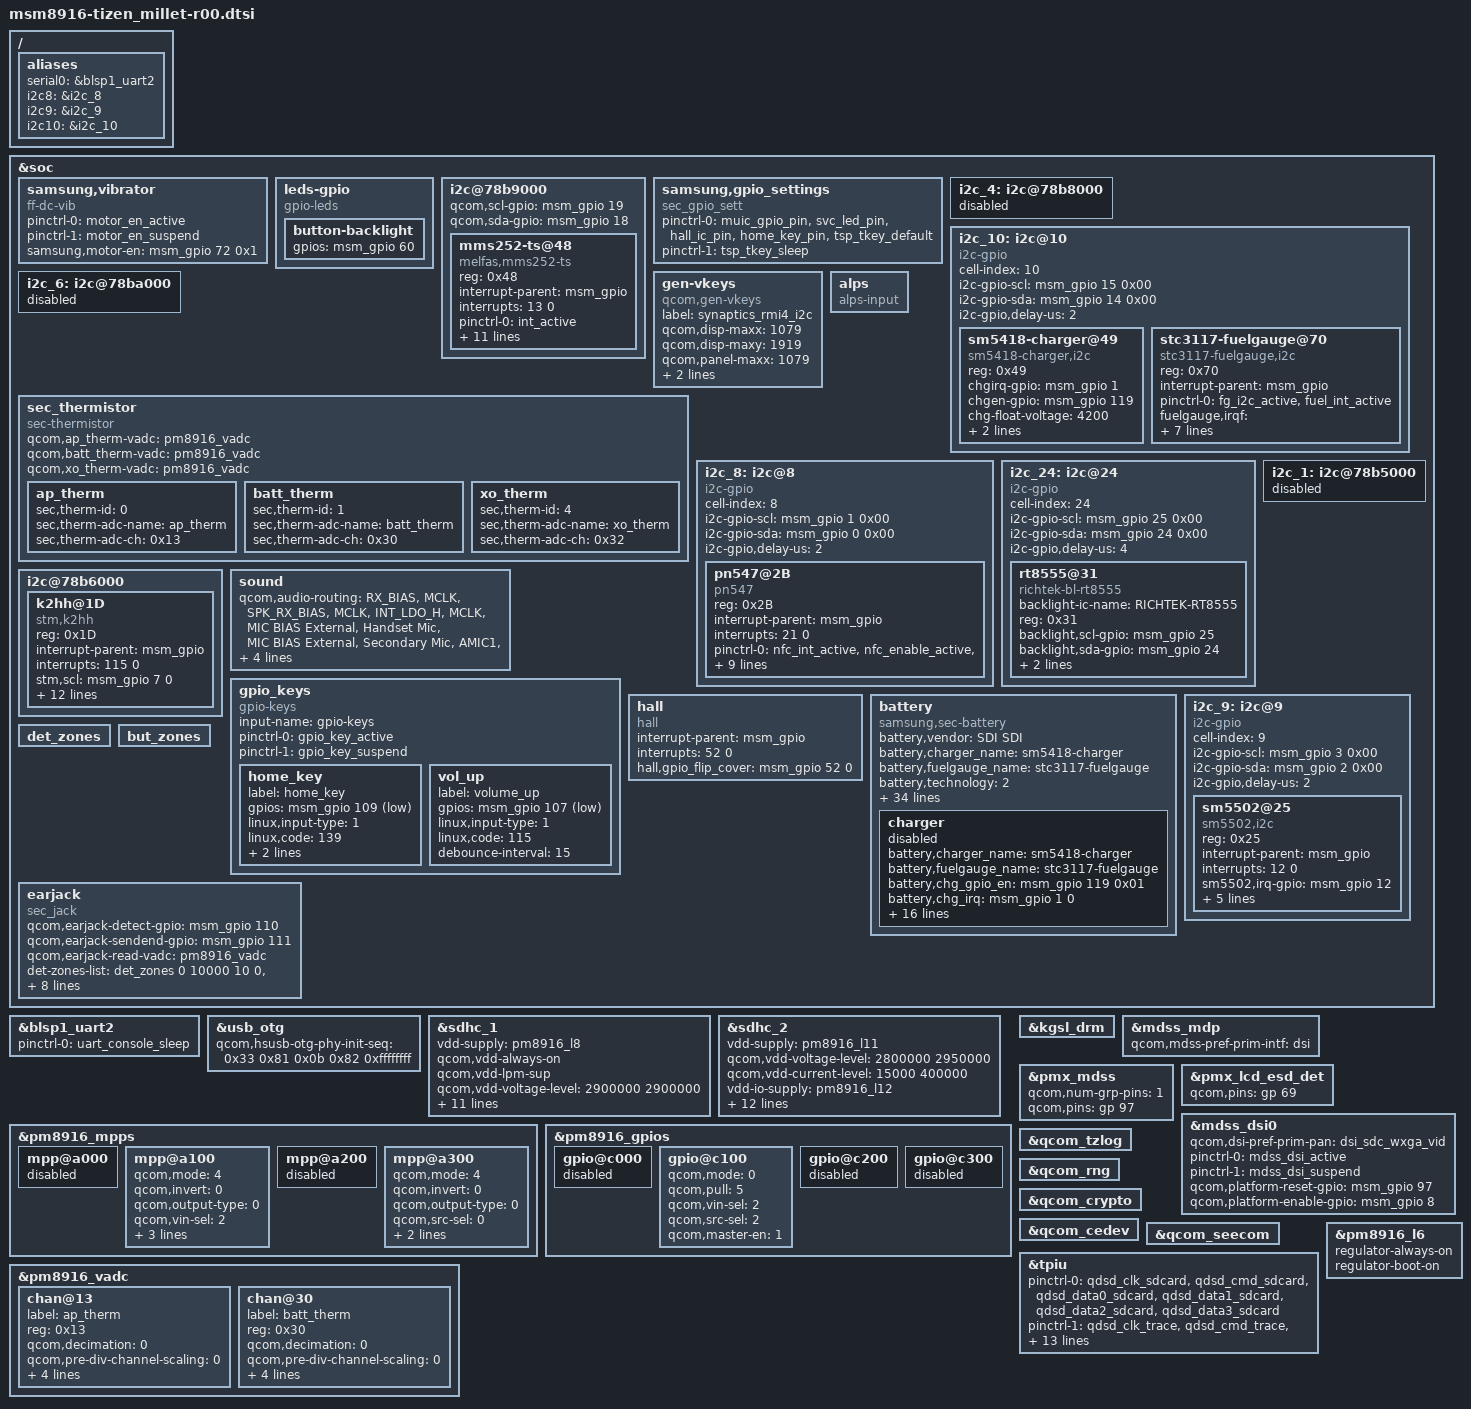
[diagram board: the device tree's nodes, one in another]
/* Copyright (c) 2014, The Linux Foundation. All rights reserved.
 *
 * This program is free software; you can redistribute it and/or modify
 * it under the terms of the GNU General Public License version 2 and
 * only version 2 as published by the Free Software Foundation.
 *
 * This program is distributed in the hope that it will be useful,
 * but WITHOUT ANY WARRANTY; without even the implied warranty of
 * MERCHANTABILITY or FITNESS FOR A PARTICULAR PURPOSE.  See the
 * GNU General Public License for more details.
 */

#include "msm8916.dtsi"
#include "msm8916-pinctrl-tizen-millet-r00.dtsi"
#include "msm8916-w1-r00.dtsi"
#include "msm8916-camera-millet.dtsi"
#include "msm8916-camera-sensor-cdp-millet.dtsi"

/ {
	aliases {
		serial0 = &blsp1_uart2;

		/*i2c-gpio bus_id*/
                i2c8 = &i2c_8;
		/*i2c3 = &i2c_3;*/
		i2c9 = &i2c_9;
		i2c10 = &i2c_10;
	};
};

&soc {
	samsung,vibrator {
		pinctrl-names = "tlmm_motor_en_active","tlmm_motor_en_suspend";
		pinctrl-0 = <&motor_en_active>;
		pinctrl-1 = <&motor_en_suspend>;
		compatible = "ff-dc-vib";
		samsung,motor-en = <&msm_gpio 72 0x1>;
		status = "ok";
	};

	leds-gpio{
		compatible = "gpio-leds";
		button-backlight{
			gpios = <&msm_gpio 60 0>;
			status = "ok";
		};
	};

	i2c@78b9000 { /* BLSP1 QUP5 */
		qcom,scl-gpio = <&msm_gpio 19 0>;
		qcom,sda-gpio = <&msm_gpio 18 0>;
		status = "okay";
		mms252-ts@48 {
				compatible = "melfas,mms252-ts";
				reg = <0x48>; /*slave address*/
				interrupt-parent = <&msm_gpio>;
				interrupts = <13 0>; /* Touch int gpio */
				pinctrl-names = "tsp_int_active", "tsp_gpio_active", "tsp_gpio_suspend";
				pinctrl-0 = <&int_active>;
				pinctrl-1 = <&tsp_en_active>;
				pinctrl-2 = <&tsp_en_suspend>;
				vdd_en-gpio = <&msm_gpio 73 0x01>; /*Touch En 1 gpio*/
				vdd_en2-gpio = <&msm_gpio 98 0x01>; /* Touch En2 gpio */
				tsp_vendor1-gpio = <&msm_gpio 55 0x00>; /*TSP Vendor1 GPIO*/
				tsp_vendor2-gpio = <&msm_gpio 56 0x00>; /*TSP Vendor2 GPIO */
				melfas,irq-gpio = <&msm_gpio 13 0x00>; /*TSP IRQ GPIO */
				melfas,panel-coords = <0  0 800 1280>;
				melfas,config_fw_version = "melfas mms252";
				melfas,i2c-pull-up = <1>;
				melfas,key1 = <169>;
                };
	};

	samsung,gpio_settings{
		compatible = "sec_gpio_sett";
		pinctrl-names = "sec_gpio_active","sec_gpio_suspend";
		pinctrl-0 = <&muic_gpio_pin &svc_led_pin &hall_ic_pin &home_key_pin &tsp_tkey_default>;
		pinctrl-1 = <&tsp_tkey_sleep>;
	};

	i2c_4: i2c@78b8000 { /* BLSP1 QUP4 */
		status="disable";
	};

       i2c_10:i2c@10 {
		cell-index = <10>;
		compatible = "i2c-gpio";
		i2c-gpio-scl = <&msm_gpio 15 0x00>;
		i2c-gpio-sda = <&msm_gpio 14 0x00>;
		i2c-gpio,delay-us = <2>;
		#address-cells = <1>;
		#size-cells = <0>;

		sm5418-charger@49{
			compatible = "sm5418-charger,i2c";
			reg = <0x49>;
			chgirq-gpio = <&msm_gpio 1 0>;
			chgen-gpio = <&msm_gpio 119 0>;
			chg-float-voltage = <4200>;
			chg-irq-attr = <0x00000002>;
			pinctrl-names = "default";
			pinctrl-0 = <&charger_en_active &ta_int_n_default>;
		};
		stc3117-fuelgauge@70{
			compatible = "stc3117-fuelgauge,i2c";
			reg = <0x70>;
			interrupt-parent = <&msm_gpio>;
			pinctrl-names = "default";
			pinctrl-0 = <&fg_i2c_active &fuel_int_active>;
			fuelgauge,irqf = "IRQF_TRIGGER_FALLING + IRQF_ONESHOT + IRQF_NO_SUSPEND";
			fuelgauge,fuel_int = <&msm_gpio 121 0x1>;
			fuelgauge,capacity_max = <1000>;
			fuelgauge,capacity_max_margin = <50>;
			fuelgauge,capacity_min = <0>;
			fuelgauge,capacity_calculation_type = <0x17>;
			fuelgauge,fuel_alert_soc = <1>;
		};
	};

	i2c_6: i2c@78ba000 { /* BLSP1 QUP6 */
		status="disable";
	};

	gen-vkeys {
		compatible = "qcom,gen-vkeys";
		label = "synaptics_rmi4_i2c";
		qcom,disp-maxx = <1079>;
		qcom,disp-maxy = <1919>;
		qcom,panel-maxx = <1079>;
		qcom,panel-maxy = <2084>;
		qcom,key-codes = <158 139 172 217>;
	};

	sec_thermistor {
		compatible = "sec-thermistor";
		qcom,ap_therm-vadc = <&pm8916_vadc>;
		qcom,batt_therm-vadc = <&pm8916_vadc>;
		qcom,xo_therm-vadc = <&pm8916_vadc>;
		ap_therm {
			sec,therm-id = <0>; /* SEC_THERM_AP */
			sec,therm-adc-name = "ap_therm";
			sec,therm-adc-ch = <0x13>; /* MPP4 */
		};
		batt_therm {
			sec,therm-id = <1>; /* SEC_THERM_BATTERY */
			sec,therm-adc-name = "batt_therm";
			sec,therm-adc-ch = <0x30>; /* LR_MUX1_BATT_THERM */
		};
		xo_therm {
			sec,therm-id = <4>; /* SEC_THERM_XO */
			sec,therm-adc-name = "xo_therm";
			sec,therm-adc-ch = <0x32>;
		};
	};

	alps {
			compatible = "alps-input";
	};

	i2c_8: i2c@8 {
		cell-index = <8>;
                compatible = "i2c-gpio";
                i2c-gpio-scl = <&msm_gpio 1 0x00>;
                i2c-gpio-sda = <&msm_gpio 0 0x00>;
                #address-cells = <1>;
                #size-cells = <0>;
		i2c-gpio,delay-us = <2>;
		pn547@2B {
			compatible = "pn547";
			reg = <0x2B>;
			interrupt-parent = <&msm_gpio>;
			interrupts = <21 0>;
			pinctrl-names = "nfc_active","nfc_suspend";
			pinctrl-0 = <&nfc_int_active &nfc_enable_active &nfc_firmware_active &nfc_i2c_active>;
			pinctrl-1 = <&nfc_int_suspend &nfc_enable_suspend &nfc_firmware_suspend &nfc_i2c_suspend>;
			pn547,firm-gpio = <&msm_gpio 49 0x00>;
			pn547,ven-gpio = <&msm_gpio 20 0x00>;
			pn547,irq-gpio = <&msm_gpio 21 0x01>;
			nfc_ldo-supply = <&pm8916_l14>;
			clocks = <&clock_rpm clk_bb_clk2_pin>;
			clock-names = "nfc_clock";
		};
	};

	i2c_24: i2c@24 {
		cell-index = <24>;
		compatible = "i2c-gpio";
		i2c-gpio-scl = <&msm_gpio 25  0x00>; /*scl gpio*/
		i2c-gpio-sda = <&msm_gpio 24 0x00>;  /*sda gpio*/
                #address-cells = <1>;
                #size-cells = <0>;
		i2c-gpio,delay-us = <4>;
		rt8555@31 {
			compatible = "richtek-bl-rt8555";
			backlight-ic-name = "RICHTEK-RT8555";
			reg = <0x31>;
			backlight,scl-gpio = <&msm_gpio 25 0x00>;
			backlight,sda-gpio = <&msm_gpio 24 0x00>;
			backlight-en-gpio = <&msm_gpio 69 0x00>;
			backlight-i2c-bl-control = [
					04 00
					00 02
			];
		};
	};

	/*i2c_3: i2c@3 {
		cell-index = <3>;
                compatible = "i2c-gpio";
		i2c-gpio-scl = <&msm_gpio 17 0x00>;
                i2c-gpio-sda = <&msm_gpio 16 0x00>;
                i2c-gpio,delay-us = <2>;
                #address-cells = <1>;
                #size-cells = <0>;

		svc_leds@30{
			compatible = "ktd2026";
			reg = <0x30>;
		};
	};*/

	i2c@78b6000 { /* BLSP1 QUP2 */
		status = "ok";
		k2hh@1D {
			compatible = "stm,k2hh";
			reg = <0x1D>;
			interrupt-parent = <&msm_gpio>;
			interrupts = <115 0>;
			stm,scl = <&msm_gpio 7 0>;
			stm,sda = <&msm_gpio 6 0>;
			stm,irq_gpio = <&msm_gpio 115 0x00>;
			stm,reg_vdd = "8916_l17";
			stm,reg_vio = "8916_l5";
			stm,axis_map_x = <1>;
			stm,axis_map_y = <0>;
			stm,axis_map_z = <2>;
			stm,negate_x = <1>;
			stm,negate_y = <0>;
			stm,negate_z = <1>;
			stm,poll_interval = <100>;
			stm,min_interval = <2>;
		};
	};

	/* Over-riding model specific changes */
	sound {
		qcom,audio-routing =
			"RX_BIAS", "MCLK",
			"SPK_RX_BIAS", "MCLK",
			"INT_LDO_H", "MCLK",
			"MIC BIAS External", "Handset Mic",
			"MIC BIAS External", "Secondary Mic",
			"AMIC1", "MIC BIAS External",
			"AMIC2", "Headset Mic",
			"AMIC3", "MIC BIAS External";
		pinctrl-names = "cdc_lines_act",
				"cdc_lines_sus";
		pinctrl-0 = <&cdc_pdm_lines_act>;
		pinctrl-1 = <&cdc_pdm_lines_sus>;
	};
};

&blsp1_uart2 {
	status = "ok";
	pinctrl-names = "default";
	pinctrl-0 = <&uart_console_sleep>;
};

&soc {
	gpio_keys {
		compatible = "gpio-keys";
		input-name = "gpio-keys";
		pinctrl-names = "tlmm_gpio_key_active","tlmm_gpio_key_suspend";
		pinctrl-0 = <&gpio_key_active>;
		pinctrl-1 = <&gpio_key_suspend>;

		home_key {
			label = "home_key";
			gpios = <&msm_gpio 109 0x1>;
			linux,input-type = <1>;
			linux,code = <139>;
			gpio-key,wakeup;
			debounce-interval = <15>;
		};
		vol_up {
			label = "volume_up";
			gpios = <&msm_gpio 107 0x1>;
			linux,input-type = <1>;
			linux,code = <115>;
			debounce-interval = <15>;
		};
	};

	hall {
		status = "okay";
		compatible = "hall";
		interrupt-parent = <&msm_gpio>;
		interrupts = <52 0>;
		hall,gpio_flip_cover = <&msm_gpio 52 0>;

	};

	battery {
		status = "okay";
		compatible = "samsung,sec-battery";
		battery,vendor = "SDI SDI";
		battery,charger_name = "sm5418-charger";
		battery,fuelgauge_name = "stc3117-fuelgauge";
		battery,technology = <2>; /* POWER_SUPPLY_TECHNOLOGY_LION */

		battery,chip_vendor = "QCOM";
		battery,temp_adc_type = <1>; /* SEC_BATTERY_ADC_TYPE_AP */

		battery,polling_time = <10 30 30 30 3600>;

		battery,adc_check_count = <5>;

		battery,cable_check_type = <4>; /* SEC_BATTERY_CABLE_CHECK_PSY */
		battery,cable_source_type = <3>; /* SEC_BATTERY_CABLE_SOURCE_EXTERNAL */
		battery,event_check;
		battery,event_waiting_time = <600>;
		battery,polling_type = <1>; /* SEC_BATTERY_MONITOR_ALARM */
		battery,monitor_initial_count = <3>;

		battery,battery_check_type = <0>; /* SEC_BATTERY_CHECK_NONE */
		battery,check_count = <0>;
		battery,check_adc_max = <1440>;
		battery,check_adc_min = <0>;

		battery,ovp_uvlo_check_type = <3>; /* SEC_BATTERY_OVP_UVLO_CHGPOLLING */

		battery,thermal_source = <2>; /* SEC_BATTERY_THERMAL_SOURCE_ADC */
		battery,temp_check_type = <2>; /* SEC_BATTERY_TEMP_CHECK_TEMP */
		battery,temp_check_count = <1>;
		battery,full_check_type = <2>; /* SEC_BATTERY_FULLCHARGED_FG_CURRENT */
		battery,full_check_type_2nd = <3>; /* SEC_BATTERY_FULLCHARGED_TIME */
		battery,full_check_count = <1>;
		battery,chg_gpio_full_check = <0>;
		battery,chg_polarity_full_check = <1>;

		/* SEC_BATTERY_FULL_CONDITION_SOC |
		   SEC_BATTERY_FULL_CONDITION_NOTIMEFULL |
		   SEC_BATTERY_FULL_CONDITION_VCELL */
		battery,full_condition_type = <13>;
		battery,full_condition_soc = <95>;
		battery,full_condition_vcell = <4250>;

		battery,recharge_check_count = <1>;
		battery,recharge_condition_type = <4>; /* SEC_BATTERY_RECHARGE_CONDITION_VCELL */
		battery,recharge_condition_soc = <98>;
		battery,recharge_condition_vcell = <4300>;

		battery,charging_total_time = <21600>;
		battery,recharging_total_time = <5400>;
		battery,charging_reset_time = <0>;
		qcom,sec-battery-vadc = <&pm8916_vadc>;

		charger{
			status = "disable";
			/* Charger */
			battery,charger_name = "sm5418-charger";
			battery,fuelgauge_name = "stc3117-fuelgauge";
			battery,chg_gpio_en = <&msm_gpio 119 0x01>;
			battery,chg_irq = <&msm_gpio 1 0>;
			battery,chg_irq_attr = <0x2002>;
			battery,chg_polarity_en = <0>;
			battery,chg_gpio_status = <0>;
			battery,chg_polarity_status = <0>;
			battery,chg_float_voltage = <4350>;
			battery,ovp_uvlo_check_type = <4>; /* SEC_BATTERY_OVP_UVLO_CHGINT */
			battery,full_check_type = <2>; /* SEC_BATTERY_FULLCHARGED_FG_CURRENT */
			battery,full_check_type_2nd = <3>; /* SEC_BATTERY_FULLCHARGED_TIME */
			battery,input_current_limit = <1050 460 460 1050 460 900 1050 460 460 1050 650 1050 1050 460 500 300 700 1050 300 1050 1050 460 460>;
			battery,fast_charging_current = <2100 0 460 2100 460 1200 1000 460 0 1200 750 2100 2100 (-1) 500 300 700 1300 300 1000 2100 0 0>;
			battery,full_check_current_1st = <223 0 223 223 223 223 223 223 0 223 223 223 223 0 223 223 223 223 223 223 223 0 0>;
			battery,full_check_current_2nd = <2400 0 2400 2400 2400 2400 2400 2400 0 2400 2400 2400 2400 0 2400 2400 2400 2400 2400 2400 2400 0 0>;
		};
	};

	i2c_1: i2c@78b5000 { /* BLSP1 QUP1 */
		status="disable";
	};

	i2c_9:i2c@9 { /*SM5502 GPIO-I2C*/
		cell-index = <9>;
		compatible = "i2c-gpio";
		i2c-gpio-scl = <&msm_gpio 3 0x00>;
		i2c-gpio-sda = <&msm_gpio 2 0x00>;
		i2c-gpio,delay-us = <2>;
		#address-cells = <1>;
		#size-cells = <0>;

		sm5502@25{
			compatible = "sm5502,i2c";
			reg = <0x25>;
			interrupt-parent = <&msm_gpio>;
			interrupts= <12 0>;
			sm5502,irq-gpio = <&msm_gpio 12 0x00>;
			sm5502,gpio-sda = <&msm_gpio 2 0x00>;
			sm5502,gpio-scl = <&msm_gpio 3 0x00>;
			sm5502,uarton-gpio = <&msm_gpio 113 0x00>;
			pinctrl-names = "sm5502_i2c_active","sm5502_i2c_suspend";
			pinctrl-0 = <&muic_i2c_active &muic_int_pin>;
			pinctrl-1 = <&muic_i2c_suspend &muic_int_pin>;
		};
	};

	det_zones: det_zones {
		#list-det-cells = <4>;
	};

	but_zones: but_zones {
		#list-but-cells = <3>;
	};

	earjack {
		compatible = "sec_jack";
		qcom,earjack-detect-gpio = <&msm_gpio 110 0x0>;
		qcom,earjack-sendend-gpio = <&msm_gpio 111 0x0>;
		qcom,earjack-read-vadc = <&pm8916_vadc>;

		det-zones-list = <&det_zones 0 10000 10 0>,
				 <&det_zones 998 10000 10 0>,
				 <&det_zones 999 10000 10 1>,
				 <&det_zones 1820 10000 10 1>;
		but-zones-list = <&but_zones 0 0 333>,
				 <&but_zones 1 334 474>,
				 <&but_zones 2 475 841>;
		mpp-channel-scaling = <2 1 1>;
		pinctrl-names = "earjack_gpio_active","earjack_gpio_suspend";
		pinctrl-0 = <&earjack_det_act &earjack_switch_act>;
		pinctrl-1 = <&earjack_det_sus &earjack_switch_sus>;
	};
};

&usb_otg {
	qcom,hsusb-otg-phy-init-seq =
					<0x33 0x81 0x0b 0x82 0xffffffff>;
};

&sdhc_1 {
	vdd-supply = <&pm8916_l8>;
	qcom,vdd-always-on;
	qcom,vdd-lpm-sup;
	qcom,vdd-voltage-level = <2900000 2900000>;
	qcom,vdd-current-level = <200 400000>;

	vdd-io-supply = <&pm8916_l5>;
	qcom,vdd-io-always-on;
	qcom,vdd-io-lpm-sup;
	qcom,vdd-io-voltage-level = <1800000 1800000>;
	qcom,vdd-io-current-level = <200 60000>;

	pinctrl-names = "active", "sleep";
	pinctrl-0 = <&sdc1_clk_on &sdc1_cmd_on &sdc1_data_on>;
	pinctrl-1 = <&sdc1_clk_off &sdc1_cmd_off &sdc1_data_off>;

	qcom,nonremovable;

	status = "ok";
};

&sdhc_2 {
	vdd-supply = <&pm8916_l11>;
	qcom,vdd-voltage-level = <2800000 2950000>;
	qcom,vdd-current-level = <15000 400000>;

	vdd-io-supply = <&pm8916_l12>;
	qcom,vdd-io-voltage-level = <1800000 2950000>;
	qcom,vdd-io-current-level = <200 50000>;

	pinctrl-names = "active", "sleep";
	pinctrl-0 = <&sdc2_clk_on &sdc2_cmd_on &sdc2_data_on &sdc2_cd_on>;
	pinctrl-1 = <&sdc2_clk_off &sdc2_cmd_off &sdc2_data_off &sdc2_cd_off>;

	#address-cells = <0>;
	interrupt-parent = <&sdhc_2>;
	interrupts = <0 1 2>;
	#interrupt-cells = <1>;
	interrupt-map-mask = <0xffffffff>;
	interrupt-map = <0 &intc 0 125 0
			1 &intc 0 221 0
			2 &msm_gpio 38 0>;
	interrupt-names = "hc_irq", "pwr_irq", "status_irq";
	cd-gpios = <&msm_gpio 38 0x1>;

	status = "ok";
};

&pm8916_mpps {
	mpp@a000 { /* MPP 1 */
		/* VDD_PX */
		status = "disabled";
	};

	mpp@a100 { /* MPP 2 */
		status = "ok";
		qcom,mode = <4>; // AIN input
		qcom,invert = <0>; //No Invert
		qcom,output-type = <0>; //CMOS
		qcom,vin-sel = <2>; //PM8971_S3 1.8v
		qcom,src-sel = <0>; //MPP Constant
		qcom,ain-route = <1>; // QPNP_PIN_AIN_AMUX_CH6 = 1 for MPP2
		qcom,master-en = <1>; // Function constant
	};

	mpp@a200 { /* MPP 3 */
		/* VREF DAC */
		status = "disabled";
	};

	mpp@a300 { /* MPP 4 */
		status = "ok";
		qcom,mode = <4>; // AIN input
		qcom,invert = <0>; //No Invert
		qcom,output-type = <0>; //CMOS
		qcom,src-sel = <0>; //MPP Constant
		qcom,ain-route = <3>; // QPNP_PIN_AIN_AMUX_CH8 = 3 for MPP4
		qcom,master-en = <1>; // Function constant
	};
};

&pm8916_gpios {
	gpio@c000 { /* GPIO 1 */
		/* Battery UICC Alarm */
		status = "disabled";
	};

	gpio@c100 { /* GPIO 2 */
		/* NFC_CLK_REQ */
		qcom,mode = <0>; /* QPNP_PIN_MODE_DIG_IN */
		qcom,pull = <5>; /* QPNP_PIN_PULL_NO */
		qcom,vin-sel = <2>; /* QPNP_PIN_VIN2 */
		qcom,src-sel = <2>; /* QPNP_PIN_SEL_FUNC_1 */
		qcom,master-en = <1>;
	};

	gpio@c200 { /* GPIO 3 */
		/* External regulator control for WTR */
		status = "disabled";
	};

	gpio@c300 { /* GPIO 4 */
		/* External regulator control for APC */
		status = "disabled";
	};
};

&kgsl_drm {
	status="okay";
};

#include "dsi-panel-s6d7aa0-wxga-video.dtsi"

&mdss_mdp {
	qcom,mdss-pref-prim-intf = "dsi";
};


&pmx_mdss {
	qcom,num-grp-pins = <1>;
	qcom,pins = <&gp 97>;
};

&pmx_lcd_esd_det {
	qcom,pins = <&gp 69>;
};

&mdss_dsi0 {
	qcom,dsi-pref-prim-pan = <&dsi_sdc_wxga_vid>;
	pinctrl-names = "mdss_default", "mdss_sleep";
	pinctrl-0 = <&mdss_dsi_active>;
	pinctrl-1 = <&mdss_dsi_suspend>;
	qcom,platform-reset-gpio = <&msm_gpio 97 0>;
	qcom,platform-enable-gpio = <&msm_gpio 8 0>;
};

&qcom_tzlog {
	status = "okay";
};

&qcom_rng {
	status = "okay";
};

&qcom_crypto {
	status = "okay";
};

&qcom_cedev {
	status = "okay";
};

&qcom_seecom {
	status = "okay";
};

/* CoreSight */
&tpiu {
      pinctrl-names = "sdcard", "trace", "swduart",
		      "swdtrc", "jtag", "spmi";
       /* NIDnT */
      pinctrl-0 = <&qdsd_clk_sdcard &qdsd_cmd_sdcard
                  &qdsd_data0_sdcard &qdsd_data1_sdcard
                  &qdsd_data2_sdcard &qdsd_data3_sdcard>;
      pinctrl-1 = <&qdsd_clk_trace &qdsd_cmd_trace
                  &qdsd_data0_trace &qdsd_data1_trace
                  &qdsd_data2_trace &qdsd_data3_trace>;
      pinctrl-2 = <&qdsd_cmd_swduart &qdsd_data0_swduart
                  &qdsd_data1_swduart &qdsd_data2_swduart
                  &qdsd_data3_swduart>;
      pinctrl-3 = <&qdsd_clk_swdtrc &qdsd_cmd_swdtrc
                  &qdsd_data0_swdtrc &qdsd_data1_swdtrc
                  &qdsd_data2_swdtrc &qdsd_data3_swdtrc>;
      pinctrl-4 = <&qdsd_cmd_jtag &qdsd_data0_jtag
                  &qdsd_data1_jtag &qdsd_data2_jtag
                  &qdsd_data3_jtag>;
      pinctrl-5 = <&qdsd_clk_spmi &qdsd_cmd_spmi
                  &qdsd_data0_spmi &qdsd_data3_spmi>;
};

&pm8916_l6 {
	regulator-always-on;
	regulator-boot-on;
};

&pm8916_vadc {
	chan@13 {
		label = "ap_therm";
		reg = <0x13>; // channel 19 for MPP4 , 1:1scale
		qcom,decimation = <0>;
		qcom,pre-div-channel-scaling = <0>; // 1:1scale
		qcom,calibration-type = "ratiometric";
		qcom,scale-function = <1>;
		qcom,hw-settle-time = <2>;
		qcom,fast-avg-setup = <0>;
	};

	chan@30 {
		label = "batt_therm";
		reg = <0x30>; // LR_MUX1_BATT_THERM , 1:1scale
		qcom,decimation = <0>;
		qcom,pre-div-channel-scaling = <0>; // 1:1scale
		qcom,calibration-type = "ratiometric";
		qcom,scale-function = <1>;
		qcom,hw-settle-time = <2>;
		qcom,fast-avg-setup = <0>;
	};
};
